# cpsw_9xuss_j7am0_CPSW_NUSS_VBUSP register map
Vendor: Texas Instruments
Peripheral module from a debugger description file (folder J7_AHP).
Registers are 32-bit, read-write, reset 0x0 unless marked. A register's access mark holds for its fields unless they carry their own. Offsets are as the file gives them; lines under a group give offsets from that group; [hi:lo] are bit positions; {n}, {i} and the like mark numbered series; 'fields as' and 'values as' point back to an identical list; <NAME> marks a mode.

## cpsw_9xuss_j7am0_CPSW_NUSS_VBUSP (part 1 of 3)
0x34 CPSW_NUSS_VBUSP_P0_LPI2WAKE_REG
  [23:0] COUNT — Port 0 EEE LPI to wake counter load value
0x34 CPSW_NUSS_VBUSP_PN_LPI2WAKE_REG
  [23:0] COUNT — EEE LPI to wake counter load value
0x34 CPSW_NUSS_VBUSP_PN_LPI2WAKE_REG
  [23:0] COUNT — EEE LPI to wake counter load value
0x34 CPSW_NUSS_VBUSP_PN_LPI2WAKE_REG
  [23:0] COUNT — EEE LPI to wake counter load value
0x34 CPSW_NUSS_VBUSP_PN_LPI2WAKE_REG
  [23:0] COUNT — EEE LPI to wake counter load value
0x34 CPSW_NUSS_VBUSP_PN_LPI2WAKE_REG
  [23:0] COUNT — EEE LPI to wake counter load value
0x34 CPSW_NUSS_VBUSP_PN_LPI2WAKE_REG
  [23:0] COUNT — EEE LPI to wake counter load value
0x34 CPSW_NUSS_VBUSP_PN_LPI2WAKE_REG
  [23:0] COUNT — EEE LPI to wake counter load value
0x34 CPSW_NUSS_VBUSP_PN_LPI2WAKE_REG
  [23:0] COUNT — EEE LPI to wake counter load value
0x34 CPSW_NUSS_VBUSP_TXGOODFRAMES
  [31:0] COUNT — Total number of good frames transmitted
0x34 CPSW_NUSS_VBUSP_EVENT_0_REG ro
  [31:0] TIME_STAMP
0x34 CPSW_NUSS_VBUSP_ALE_TBLW2
  [10:0] TABLEWRD2 — Table Entry bits [75:64]
0x38 CPSW_NUSS_VBUSP_AUX_CFG_REG
  [31:0] AUX_CFG — Auxiliary configuration register output
0x38 CPSW_NUSS_VBUSP_POLL_EN_REG reset 0xFFFFFFFF
  [31:0] POLL_EN — MDIO Poll Enable
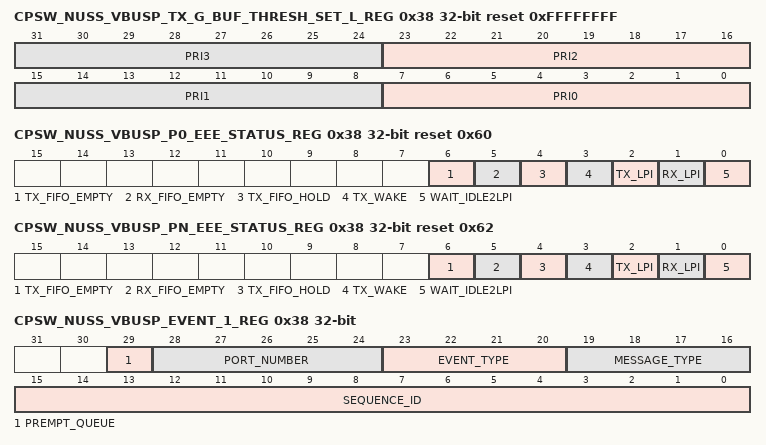
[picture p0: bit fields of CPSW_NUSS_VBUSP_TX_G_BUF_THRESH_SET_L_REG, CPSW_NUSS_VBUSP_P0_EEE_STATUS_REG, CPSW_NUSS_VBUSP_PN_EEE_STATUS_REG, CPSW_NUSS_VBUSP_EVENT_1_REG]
0x38 CPSW_NUSS_VBUSP_TX_G_BUF_THRESH_SET_L_REG reset 0xFFFFFFFF
  [8n+7:8n] PRI{n} (n=0..3) — Priority Based Flow Control Global Buffer Usage Threshold for Priority {n}
0x38 CPSW_NUSS_VBUSP_P0_EEE_STATUS_REG ro reset 0x60
  [6] TX_FIFO_EMPTY — CPPI port 0 transmit FIFO (switch egress) is empty - contains no packets
  [5] RX_FIFO_EMPTY — CPPI port 0 receive FIFO (switch ingress) is empty - contains no packets
  [4] TX_FIFO_HOLD — CPPI port 0 transmit FIFO hold - asserted in the LPI state and during the LPI2WAKE count time
  [3] TX_WAKE — CPPI port 0 transmit wakeup - asserted in the transmit LPI2WAKE count time
  [2] TX_LPI — CPPI port 0 transmit LPI state - asserted when the port 0 transmit is in the LPI state
  [1] RX_LPI — CPPI port 0 receive LPI state - asserted when the port 0 receive is in the LPI state
  [0] WAIT_IDLE2LPI — CPPI port 0 wait idle to LPI - asserted when port 0 is counting the IDLE2LPI time
0x38 CPSW_NUSS_VBUSP_PN_EEE_STATUS_REG ro reset 0x62
  [6] TX_FIFO_EMPTY — Transmit FIFO (switch egress) is empty - contains no packets
  [5] RX_FIFO_EMPTY — Receive FIFO (switch ingress) is empty - contains no packets
  [4] TX_FIFO_HOLD — Transmit FIFO hold - asserted in the LPI state and during the LPI2WAKE count time
  [3] TX_WAKE — Transmit wakeup - asserted in the transmit LPI2WAKE count time
  [2] TX_LPI — Transmit LPI state - asserted when the port 0 transmit is in the LPI state
  [1] RX_LPI — Receive LPI state - asserted when the port 0 receive is in the LPI state
  [0] WAIT_IDLE2LPI — CPPI port 0 wait idle to LPI - asserted when port 0 is counting the IDLE2LPI time
0x38 CPSW_NUSS_VBUSP_PN_EEE_STATUS_REG ro reset 0x62
  fields as CPSW_NUSS_VBUSP_PN_EEE_STATUS_REG
0x38 CPSW_NUSS_VBUSP_PN_EEE_STATUS_REG ro reset 0x62
  fields as CPSW_NUSS_VBUSP_PN_EEE_STATUS_REG
0x38 CPSW_NUSS_VBUSP_PN_EEE_STATUS_REG ro reset 0x62
  fields as CPSW_NUSS_VBUSP_PN_EEE_STATUS_REG
0x38 CPSW_NUSS_VBUSP_PN_EEE_STATUS_REG ro reset 0x62
  fields as CPSW_NUSS_VBUSP_PN_EEE_STATUS_REG
0x38 CPSW_NUSS_VBUSP_PN_EEE_STATUS_REG ro reset 0x62
  fields as CPSW_NUSS_VBUSP_PN_EEE_STATUS_REG
0x38 CPSW_NUSS_VBUSP_PN_EEE_STATUS_REG ro reset 0x62
  fields as CPSW_NUSS_VBUSP_PN_EEE_STATUS_REG
0x38 CPSW_NUSS_VBUSP_PN_EEE_STATUS_REG ro reset 0x62
  fields as CPSW_NUSS_VBUSP_PN_EEE_STATUS_REG
0x38 CPSW_NUSS_VBUSP_TXBROADCASTFRAMES
  [31:0] COUNT — Total number of good broadcast frames transmitted
0x38 CPSW_NUSS_VBUSP_EVENT_1_REG ro
  [29] PREMPT_QUEUE, [28:24] PORT_NUMBER, [23:20] EVENT_TYPE, [19:16] MESSAGE_TYPE, [15:0] SEQUENCE_ID
0x38 CPSW_NUSS_VBUSP_ALE_TBLW1
  [31:0] TABLEWRD1 — Table Entry bits [63:32]
0x3C CPSW_NUSS_VBUSP_CLAUS45_REG
  [31:0] CLAUSE45 — MDIO Clause 45
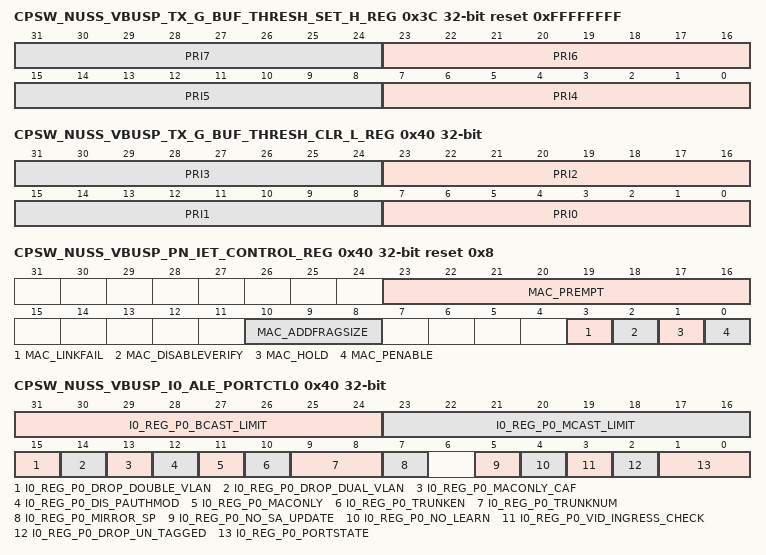
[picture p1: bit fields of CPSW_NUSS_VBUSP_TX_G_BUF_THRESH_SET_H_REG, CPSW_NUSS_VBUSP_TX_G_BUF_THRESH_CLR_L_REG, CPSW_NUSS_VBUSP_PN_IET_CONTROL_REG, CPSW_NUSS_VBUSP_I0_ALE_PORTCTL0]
0x3C CPSW_NUSS_VBUSP_TX_G_BUF_THRESH_SET_H_REG reset 0xFFFFFFFF
  [8n-25:8n-32] PRI{n} (n=4..7) — Priority Based Flow Control Global Buffer Usage Threshold for Priority {n}
0x3C CPSW_NUSS_VBUSP_TXMULTICASTFRAMES
  [31:0] COUNT — Total number of good multicast frames transmitted
0x3C CPSW_NUSS_VBUSP_EVENT_2_REG ro
  [7:0] DOMAIN
0x3C CPSW_NUSS_VBUSP_ALE_TBLW0
  [31:0] TABLEWRD0 — Table Entry bits [31:0]
0x40 CPSW_NUSS_VBUSP_DIAG_CLEAR_REG
  [0] DIAG_CLEAR — Diagnostics clear
0x40 CPSW_NUSS_VBUSP_USER_ADDR0_REG
  [15:0] USER_ADDR0 — MDIO USER Address 0
0x40 CPSW_NUSS_VBUSP_TX_G_BUF_THRESH_CLR_L_REG
  fields as CPSW_NUSS_VBUSP_TX_G_BUF_THRESH_SET_L_REG
0x40 CPSW_NUSS_VBUSP_PN_IET_CONTROL_REG reset 0x8
  [23:16] MAC_PREMPT — IET MAC Fragment Size
  [10:8] MAC_ADDFRAGSIZE — IET MAC Fragment Size
  [3] MAC_LINKFAIL — IET MAC LINK Fail Reset
  [2] MAC_DISABLEVERIFY — IET MAC Disable Verify
  [1] MAC_HOLD — IET MAC HOLD
  [0] MAC_PENABLE — IET MAC Penable
0x40 CPSW_NUSS_VBUSP_PN_IET_CONTROL_REG reset 0x8
  fields as CPSW_NUSS_VBUSP_PN_IET_CONTROL_REG
0x40 CPSW_NUSS_VBUSP_PN_IET_CONTROL_REG reset 0x8
  fields as CPSW_NUSS_VBUSP_PN_IET_CONTROL_REG
0x40 CPSW_NUSS_VBUSP_PN_IET_CONTROL_REG reset 0x8
  fields as CPSW_NUSS_VBUSP_PN_IET_CONTROL_REG
0x40 CPSW_NUSS_VBUSP_PN_IET_CONTROL_REG reset 0x8
  fields as CPSW_NUSS_VBUSP_PN_IET_CONTROL_REG
0x40 CPSW_NUSS_VBUSP_PN_IET_CONTROL_REG reset 0x8
  fields as CPSW_NUSS_VBUSP_PN_IET_CONTROL_REG
0x40 CPSW_NUSS_VBUSP_PN_IET_CONTROL_REG reset 0x8
  fields as CPSW_NUSS_VBUSP_PN_IET_CONTROL_REG
0x40 CPSW_NUSS_VBUSP_PN_IET_CONTROL_REG reset 0x8
  fields as CPSW_NUSS_VBUSP_PN_IET_CONTROL_REG
0x40 CPSW_NUSS_VBUSP_TXPAUSEFRAMES
  [31:0] COUNT — Total number of pause frames transmitted
0x40 CPSW_NUSS_VBUSP_EVENT_3_REG ro
  [31:0] TIME_STAMP
0x40 CPSW_NUSS_VBUSP_I0_ALE_PORTCTL0
  [31:24] I0_REG_P0_BCAST_LIMIT — Broadcast Packet Rate Limit - Each prescale pulse loads this field into the port broadcast rate limit counter. The port counters are decremented with each packet received or transmitted depending on whether the mode is transmit or receive. If the counters decrement to zero, then further packets are rate limited until the next prescale pulse. Broadcast rate limiting is enabled by a non-zero value in this field.
  [23:16] I0_REG_P0_MCAST_LIMIT — Multicast Packet Rate Limit - Each prescale pulse loads this field into the port multicast rate limit counter. The port counters are decremented with each packet received or transmitted depending on whether the mode is transmit or receive. If the counters decrement to zero, then further packets are rate limited until the next prescale pulse. Multicast rate limiting is enabled by a non-zero value in this field.The ~imcast_limit is the number of Multicast packets that will be forwaded per ~iale_prescale time.
  [15] I0_REG_P0_DROP_DOUBLE_VLAN — Drop Double VLAN - When set cause any received packet with double VLANs to be dropped. That is if there are two ctag or two stag fields in the packet it will be dropped.
  [14] I0_REG_P0_DROP_DUAL_VLAN — Drop Dual VLAN - When set will cause any received packet with dual VLAN stag followed by ctag to be dropped.
  [13] I0_REG_P0_MACONLY_CAF — Mac Only Copy All Frames - When set a Mac Only port will transfer all received good frames to the host. When clear a Mac Only port will transfer packets to the host based on ALE destination address lookup operation (which operates more like an Ethernet Mac). A Mac Only port is a port with ~imaconly set.
  [12] I0_REG_P0_DIS_PAUTHMOD — Disable Port authorization - When set will allow unknown addresses to arrive on a switch in authorization mode. It is intended for device to device network connection on ports which do not require MACSEC encryption.
  [11] I0_REG_P0_MACONLY — MAC Only - When set enables this port be treated like a MAC port for the host. All traffic received is only sent to the host. The host must direct traffic to this port as the lookup engine will not send traffic to the ports with the ~ip0_maconly bit set and the ~ip0_no_learn also set. If ~ip0_maconly bit is set and the ~ip0_no_learn is not set, the host can send non-directed packets that can be sent to the destination of a MacOnly port. It is also possible that The host can broadcast to all ports including MacOnly ports in this mode.
  [10] I0_REG_P0_TRUNKEN — Trunk Enable - This field is used to enable a port into a trunk. Any port can be used as a trunk port, any two or more ports with the ~ip0_trunken its set and having the same ~ip0_trunknum will be placed in the same trunk. There is no requirement for trunk ports to be adjacent. If all ports are enabled in the same trunk, no traffic can flow as traffic received within a trunk is never trasnmitted out the same trunk. If only a single port is a member of a trunk, it looks like a normal port with exception of entries in the look up table will be noted as a trunk entry.
  [9:8] I0_REG_P0_TRUNKNUM — Trunk Number - This field is used as the trunk number when the ~ip0_trunken is also set. Ports with the same trunk number that have the ~ip0_trunken also set will have traffic distributed within the trunk based on the result of the hash function descrived above.
  [7] I0_REG_P0_MIRROR_SP — Mirror Source Port - This field enables the source port mirror option. When this bit is set any traffic received on the port with the reg_p0_mirror_sp bit set will have its received traffic also sent to the ~imirror_top port.
  [5] I0_REG_P0_NO_SA_UPDATE — No Source Address Update - When set will not update the source addresses for this port.
  [4] I0_REG_P0_NO_LEARN — No Learn - When set will not learn the source addresses for this port.
  [3] I0_REG_P0_VID_INGRESS_CHECK — VLAN Ingress Check - When set if a packet received is not a member of the VLAN, the packet will be dropped.
  [2] I0_REG_P0_DROP_UN_TAGGED — If Drop Untagged - When set will drop packets without a VLAN tag.
  [1:0] I0_REG_P0_PORTSTATE — Port State - Defins the current port state used for lookup operations. 0 - Disabled 1 - Blocked 2 - Learning 3 - Forwarding
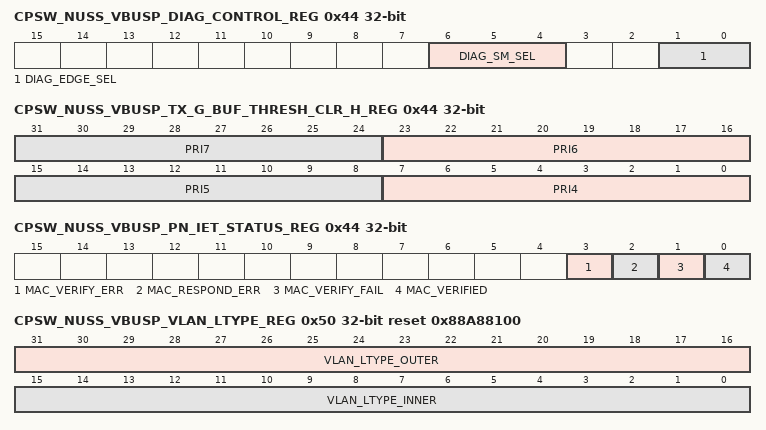
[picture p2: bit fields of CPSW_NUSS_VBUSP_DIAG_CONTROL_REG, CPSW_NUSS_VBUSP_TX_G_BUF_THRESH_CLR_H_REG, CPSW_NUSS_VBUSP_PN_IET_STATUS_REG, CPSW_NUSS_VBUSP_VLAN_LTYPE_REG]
0x44 CPSW_NUSS_VBUSP_DIAG_CONTROL_REG
  [6:4] DIAG_SM_SEL — Diagnostic select
  [1:0] DIAG_EDGE_SEL — Diagnostics hold signals edge select
0x44 CPSW_NUSS_VBUSP_USER_ADDR1_REG
  [15:0] USER_ADDR1 — MDIO USER Address 1
0x44 CPSW_NUSS_VBUSP_TX_G_BUF_THRESH_CLR_H_REG
  fields as CPSW_NUSS_VBUSP_TX_G_BUF_THRESH_SET_H_REG
0x44 CPSW_NUSS_VBUSP_PN_IET_STATUS_REG ro
  [3] MAC_VERIFY_ERR — IET MAC VERIFY ERROR
  [2] MAC_RESPOND_ERR — IET MAC RESPONSE ERROR
  [1] MAC_VERIFY_FAIL — IET MAC VERIFY FAIL
  [0] MAC_VERIFIED — IET MAC VERIFIED
0x44 CPSW_NUSS_VBUSP_PN_IET_STATUS_REG ro
  fields as CPSW_NUSS_VBUSP_PN_IET_STATUS_REG
0x44 CPSW_NUSS_VBUSP_PN_IET_STATUS_REG ro
  fields as CPSW_NUSS_VBUSP_PN_IET_STATUS_REG
0x44 CPSW_NUSS_VBUSP_PN_IET_STATUS_REG ro
  fields as CPSW_NUSS_VBUSP_PN_IET_STATUS_REG
0x44 CPSW_NUSS_VBUSP_PN_IET_STATUS_REG ro
  fields as CPSW_NUSS_VBUSP_PN_IET_STATUS_REG
0x44 CPSW_NUSS_VBUSP_PN_IET_STATUS_REG ro
  fields as CPSW_NUSS_VBUSP_PN_IET_STATUS_REG
0x44 CPSW_NUSS_VBUSP_PN_IET_STATUS_REG ro
  fields as CPSW_NUSS_VBUSP_PN_IET_STATUS_REG
0x44 CPSW_NUSS_VBUSP_PN_IET_STATUS_REG ro
  fields as CPSW_NUSS_VBUSP_PN_IET_STATUS_REG
0x44 CPSW_NUSS_VBUSP_TXDEFERREDFRAMES
  [31:0] COUNT — Total number of deferred frames transmitted
0x44 CPSW_NUSS_VBUSP_TS_LOAD_HIGH_VAL_REG
  [31:0] TS_LOAD_VAL — Time stamp load high value
0x48 CPSW_NUSS_VBUSP_DIAG_STATUS_REG ro
  [15:0] DIAG_STATUS — Diagnostics status
0x48 CPSW_NUSS_VBUSP_PN_IET_VERIFY_REG reset 0x1312D0
  [23:0] MAC_VERIFY_CNT — IET MAC VERIFY COUNT
0x48 CPSW_NUSS_VBUSP_PN_IET_VERIFY_REG reset 0x1312D0
  [23:0] MAC_VERIFY_CNT — IET MAC VERIFY COUNT
0x48 CPSW_NUSS_VBUSP_PN_IET_VERIFY_REG reset 0x1312D0
  [23:0] MAC_VERIFY_CNT — IET MAC VERIFY COUNT
0x48 CPSW_NUSS_VBUSP_PN_IET_VERIFY_REG reset 0x1312D0
  [23:0] MAC_VERIFY_CNT — IET MAC VERIFY COUNT
0x48 CPSW_NUSS_VBUSP_PN_IET_VERIFY_REG reset 0x1312D0
  [23:0] MAC_VERIFY_CNT — IET MAC VERIFY COUNT
0x48 CPSW_NUSS_VBUSP_PN_IET_VERIFY_REG reset 0x1312D0
  [23:0] MAC_VERIFY_CNT — IET MAC VERIFY COUNT
0x48 CPSW_NUSS_VBUSP_PN_IET_VERIFY_REG reset 0x1312D0
  [23:0] MAC_VERIFY_CNT — IET MAC VERIFY COUNT
0x48 CPSW_NUSS_VBUSP_PN_IET_VERIFY_REG reset 0x1312D0
  [23:0] MAC_VERIFY_CNT — IET MAC VERIFY COUNT
0x48 CPSW_NUSS_VBUSP_TXCOLLISIONFRAMES
  [31:0] COUNT — Total number of transmitted frames experiencing a collision
0x48 CPSW_NUSS_VBUSP_TS_COMP_HIGH_VAL_REG
  [31:0] TS_COMP_HIGH_VAL — Time stamp comparison high value
0x4C CPSW_NUSS_VBUSP_TXSINGLECOLLFRAMES
  [31:0] COUNT — Total number of transmitted frames experiencing a single collision
0x4C CPSW_NUSS_VBUSP_TS_ADD_VAL_REG
  [2:0] ADD_VAL — Add Value
0x50 CPSW_NUSS_VBUSP_VLAN_LTYPE_REG reset 0x88A88100
  [31:16] VLAN_LTYPE_OUTER — Outer VLAN LType
  [15:0] VLAN_LTYPE_INNER — Inner VLAN LType
0x50 CPSW_NUSS_VBUSP_P0_FIFO_STATUS_REG ro
  [7:0] TX_PRI_ACTIVE — Port 0 FIFO Status
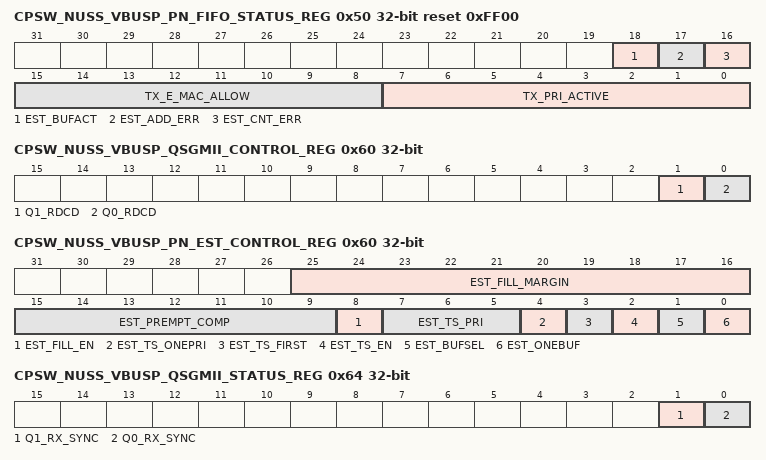
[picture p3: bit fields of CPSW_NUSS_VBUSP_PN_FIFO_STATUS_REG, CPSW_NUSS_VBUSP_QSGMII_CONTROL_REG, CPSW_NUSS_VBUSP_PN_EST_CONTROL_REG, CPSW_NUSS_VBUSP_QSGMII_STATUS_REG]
0x50 CPSW_NUSS_VBUSP_PN_FIFO_STATUS_REG ro reset 0xFF00
  [18] EST_BUFACT — Transmit FIFO EST Buffer Active
  [17] EST_ADD_ERR — Transmit FIFO EST Address Error
  [16] EST_CNT_ERR — Transmit FIFO EST Count Error
  [15:8] TX_E_MAC_ALLOW — Transmit FIFO Express Queue Priority Allow
  [7:0] TX_PRI_ACTIVE — Transmit FIFO Priority Active
0x50 CPSW_NUSS_VBUSP_PN_FIFO_STATUS_REG ro reset 0xFF00
  fields as CPSW_NUSS_VBUSP_PN_FIFO_STATUS_REG
0x50 CPSW_NUSS_VBUSP_PN_FIFO_STATUS_REG ro reset 0xFF00
  fields as CPSW_NUSS_VBUSP_PN_FIFO_STATUS_REG
0x50 CPSW_NUSS_VBUSP_PN_FIFO_STATUS_REG ro reset 0xFF00
  fields as CPSW_NUSS_VBUSP_PN_FIFO_STATUS_REG
0x50 CPSW_NUSS_VBUSP_PN_FIFO_STATUS_REG ro reset 0xFF00
  fields as CPSW_NUSS_VBUSP_PN_FIFO_STATUS_REG
0x50 CPSW_NUSS_VBUSP_PN_FIFO_STATUS_REG ro reset 0xFF00
  fields as CPSW_NUSS_VBUSP_PN_FIFO_STATUS_REG
0x50 CPSW_NUSS_VBUSP_PN_FIFO_STATUS_REG ro reset 0xFF00
  fields as CPSW_NUSS_VBUSP_PN_FIFO_STATUS_REG
0x50 CPSW_NUSS_VBUSP_PN_FIFO_STATUS_REG ro reset 0xFF00
  fields as CPSW_NUSS_VBUSP_PN_FIFO_STATUS_REG
0x50 CPSW_NUSS_VBUSP_TXMULTCOLLFRAMES
  [31:0] COUNT — Total number of transmitted frames experiencing multiple collisions
0x50 CPSW_NUSS_VBUSP_TS_PPM_LOW_VAL_REG
  [31:0] TS_PPM_LOW_VAL — Time stamp PPM Low value
0x54 CPSW_NUSS_VBUSP_EST_TS_DOMAIN_REG
  [7:0] EST_TS_DOMAIN — Enhanced Scheduled Traffic Host Event Domain
0x54 CPSW_NUSS_VBUSP_TXEXCESSIVECOLLISIONS
  [31:0] COUNT — Total number of transmitted frames abandoned due to excessive collisions
0x54 CPSW_NUSS_VBUSP_TS_PPM_HIGH_VAL_REG
  [9:0] TS_PPM_HIGH_VAL — Time stamp PPM High value
0x58 CPSW_NUSS_VBUSP_TXLATECOLLISIONS
  [31:0] COUNT — Total number of transmitted frames abandoned due to a late collision
0x58 CPSW_NUSS_VBUSP_TS_NUDGE_VAL_REG
  [7:0] TS_NUDGE_VAL — Time stamp Nudge value
0x5C CPSW_NUSS_VBUSP_RXIPGERROR
  [31:0] COUNT — Total number of receive inter-packet gap errors (10G only)
0x60 CPSW_NUSS_VBUSP_QSGMII_CONTROL_REG
  [1] Q1_RDCD — QSGMII1 Running Disparity Check Disable
  [0] Q0_RDCD — QSGMII0 Running Disparity Check Disable
0x60 CPSW_NUSS_VBUSP_PN_EST_CONTROL_REG
  [25:16] EST_FILL_MARGIN — Transmit FIFO EST Fill Margin
  [15:9] EST_PREMPT_COMP — Transmit FIFO EST Prempt Comparison Value to Clear wire
  [8] EST_FILL_EN — Transmit FIFO EST Fill Enable
  [7:5] EST_TS_PRI — Transmit FIFO EST TimeStamp Priority
  [4] EST_TS_ONEPRI — Transmit FIFO EST TimeStamp One Priority
  [3] EST_TS_FIRST — Transmit FIFO EST TimeStamp First Express Packet
  [2] EST_TS_EN — Transmit FIFO EST TimeStamp Enable
  [1] EST_BUFSEL — Transmit FIFO EST Buffer Select
  [0] EST_ONEBUF — Transmit FIFO EST One Buffer
0x60 CPSW_NUSS_VBUSP_PN_EST_CONTROL_REG
  fields as CPSW_NUSS_VBUSP_PN_EST_CONTROL_REG
0x60 CPSW_NUSS_VBUSP_PN_EST_CONTROL_REG
  fields as CPSW_NUSS_VBUSP_PN_EST_CONTROL_REG
0x60 CPSW_NUSS_VBUSP_PN_EST_CONTROL_REG
  fields as CPSW_NUSS_VBUSP_PN_EST_CONTROL_REG
0x60 CPSW_NUSS_VBUSP_PN_EST_CONTROL_REG
  fields as CPSW_NUSS_VBUSP_PN_EST_CONTROL_REG
0x60 CPSW_NUSS_VBUSP_PN_EST_CONTROL_REG
  fields as CPSW_NUSS_VBUSP_PN_EST_CONTROL_REG
0x60 CPSW_NUSS_VBUSP_PN_EST_CONTROL_REG
  fields as CPSW_NUSS_VBUSP_PN_EST_CONTROL_REG
0x60 CPSW_NUSS_VBUSP_PN_EST_CONTROL_REG
  fields as CPSW_NUSS_VBUSP_PN_EST_CONTROL_REG
0x60 CPSW_NUSS_VBUSP_TXCARRIERSENSEERRORS
  [31:0] COUNT — Total number of transmitted frames that experienced a carrier loss
0x64 CPSW_NUSS_VBUSP_QSGMII_STATUS_REG ro
  [1] Q1_RX_SYNC — QSGMII1 RX Sync Detected
  [0] Q0_RX_SYNC — QSGMII0 RX Sync Detected
0x64 CPSW_NUSS_VBUSP_TXOCTETS
  [31:0] COUNT — Total number of bytes in all good frames transmitted
0x68 CPSW_NUSS_VBUSP_OCTETFRAMES64
  [31:0] COUNT — Total number of 64-byte frames received and transmitted
0x6C CPSW_NUSS_VBUSP_OCTETFRAMES65T127
  [31:0] COUNT — Total number of frames of size 65 to 127 bytes received and transmitted
0x70 CPSW_NUSS_VBUSP_OCTETFRAMES128T255
  [31:0] COUNT — Total number of frames of size 128 to 255 bytes received and transmitted
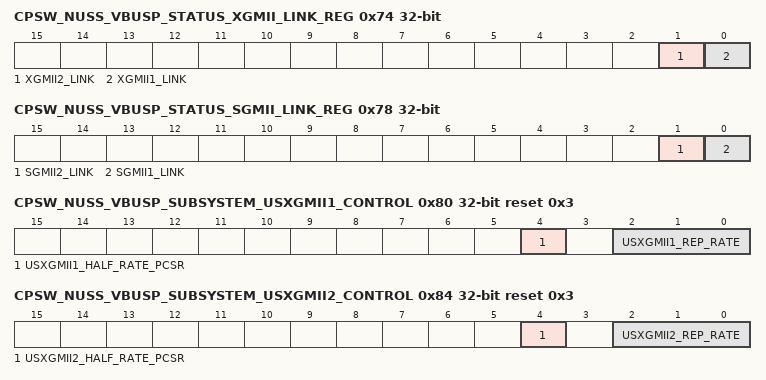
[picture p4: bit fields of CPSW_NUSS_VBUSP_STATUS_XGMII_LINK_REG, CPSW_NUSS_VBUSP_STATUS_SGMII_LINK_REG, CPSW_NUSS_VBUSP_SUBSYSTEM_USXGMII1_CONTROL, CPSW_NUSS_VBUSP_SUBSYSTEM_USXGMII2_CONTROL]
0x74 CPSW_NUSS_VBUSP_STATUS_XGMII_LINK_REG ro
  [1] XGMII2_LINK — Port 2 XGMII Link Indicator
  [0] XGMII1_LINK — Port 1 XGMII Link Indicator
0x74 CPSW_NUSS_VBUSP_OCTETFRAMES256T511
  [31:0] COUNT — Total number of frames of size 256 to 511 bytes received and transmitted
0x78 CPSW_NUSS_VBUSP_STATUS_SGMII_LINK_REG ro
  [1] SGMII2_LINK — Port 2 SGMII Link Indicator
  [0] SGMII1_LINK — Port 1 SGMII Link Indicator
0x78 CPSW_NUSS_VBUSP_OCTETFRAMES512T1023
  [31:0] COUNT — Total number of frames of size 512 to 1023 bytes received and transmitted
0x7C CPSW_NUSS_VBUSP_OCTETFRAMES1024TUP
  [31:0] COUNT — Total number of frames of size 1024 to rx_maxlen bytes received and 1024 bytes or greater transmitted
0x80 CPSW_NUSS_VBUSP_SUBSYSTEM_USXGMII1_CONTROL reset 0x3
  [4] USXGMII1_HALF_RATE_PCSR — USXGMII1 Half Rate
  [2:0] USXGMII1_REP_RATE
0x80 CPSW_NUSS_VBUSP_NETOCTETS
  [31:0] COUNT — Total number of bytes received and transmitted
0x84 CPSW_NUSS_VBUSP_SUBSYSTEM_USXGMII2_CONTROL reset 0x3
  [4] USXGMII2_HALF_RATE_PCSR — USXGMII2 Half Rate
  [2:0] USXGMII2_REP_RATE
0x84 CPSW_NUSS_VBUSP_RX_BOTTOM_OF_FIFO_DROP
  [31:0] COUNT — Receive Bottom of FIFO Drop
0x88 CPSW_NUSS_VBUSP_PORTMASK_DROP
  [31:0] COUNT — Total number of dropped frames received due to portmask
0x8C CPSW_NUSS_VBUSP_RX_TOP_OF_FIFO_DROP
  [31:0] COUNT — Receive Top of FIFO Drop
0x90 CPSW_NUSS_VBUSP_ALE_RATE_LIMIT_DROP
  [31:0] COUNT — Total number of dropped frames due to ALE Rate Limiting
0x90 CPSW_NUSS_VBUSP_ALE_UVLAN_MEMBER
  [8:0] UVLAN_MEMBER_LIST — Unknown VLAN Member List - Each bit represents the port member status for unknown VLANs.
0x94 CPSW_NUSS_VBUSP_ALE_VID_INGRESS_DROP
  [31:0] COUNT — Total number of dropped frames due to ALE VID Ingress
0x94 CPSW_NUSS_VBUSP_ALE_UVLAN_URCAST
  [8:0] UVLAN_UNREG_MCAST_FLOOD_MASK — Unknown VLAN Unregister Multicast Flood Mask - Each bit represents the port to which unregistered multicast are sent for unregistered VLANs.
0x98 CPSW_NUSS_VBUSP_ALE_DA_EQ_SA_DROP
  [31:0] COUNT — Total number of dropped frames due to DA=SA
0x98 CPSW_NUSS_VBUSP_ALE_UVLAN_RMCAST
  [8:0] UVLAN_REG_MCAST_FLOOD_MASK — Unknown VLAN Register Multicast Flood Mask - Each bit represents the port to which registered multicast are sent for unregistered VLANs. This field is ANDed with the registered multicast mask to determine the destinations for unregistered VLANs.
0x9C CPSW_NUSS_VBUSP_ALE_BLOCK_DROP
  [31:0] COUNT — Total number of dropped frames due to ALE Block Mode
0x9C CPSW_NUSS_VBUSP_ALE_UVLAN_UNTAG
  [8:0] UVLAN_FORCE_UNTAGGED_EGRESS — Unknown VLAN Force Untagged Egress Mask - Each bit represents the port where the VLAN will be removed for unregistered VLANs.
0xA0 CPSW_NUSS_VBUSP_ALE_SECURE_DROP
  [31:0] COUNT — Total number of dropped frames due to ALE Secure Mode
0xA4 CPSW_NUSS_VBUSP_ALE_AUTH_DROP
  [31:0] COUNT — Total number of dropped frames due to ALE Authentication
0xA8 CPSW_NUSS_VBUSP_ALE_UNKN_UNI
  [31:0] COUNT — ALE Receive Unknown Unicast
0xAC CPSW_NUSS_VBUSP_ALE_UNKN_UNI_BCNT
  [31:0] COUNT — ALE Receive Unknown Unicast Bytecount
0xB0 CPSW_NUSS_VBUSP_ALE_UNKN_MLT
  [31:0] COUNT — ALE Receive Unknown Multicast
0xB4 CPSW_NUSS_VBUSP_ALE_UNKN_MLT_BCNT
  [31:0] COUNT — ALE Receive Unknown Multicast Bytecount
0xB4 CPSW_NUSS_VBUSP_ALE_FAST_LUT
  [8:0] FAST_LUT — The ~Fast_LUT field alows any port to be Fast_LUT mode, which will cause all lookup operations to start based on DA/SA and VLAN only. That is any data beyong the first 32 are not used in the lookup process.
0xB8 CPSW_NUSS_VBUSP_ALE_UNKN_BRD
  [31:0] COUNT — ALE Receive Unknown Broadcast
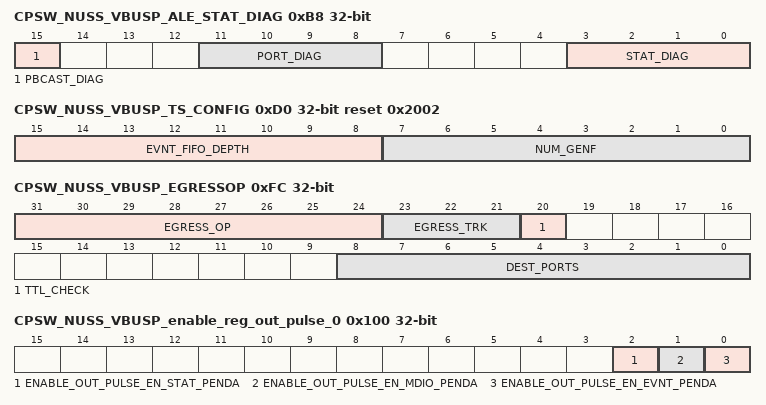
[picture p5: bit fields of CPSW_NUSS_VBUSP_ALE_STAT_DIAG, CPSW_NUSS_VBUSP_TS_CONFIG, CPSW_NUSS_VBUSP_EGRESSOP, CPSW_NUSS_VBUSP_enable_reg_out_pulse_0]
0xB8 CPSW_NUSS_VBUSP_ALE_STAT_DIAG
  [15] PBCAST_DIAG — When set and the ~iport_diag is set to zero, will allow all ports to see the same stat diagnostic increment.
  [11:8] PORT_DIAG — The port selected that a received packet will cause the selected error to increment
  [3:0] STAT_DIAG — When non-zero will cause the selected statistic to increment on the next frame received. For the selected Port. 0: Disabled 1: Destination Equal Source Drop Stat will count 2: VLAN Ingress Check Drop Stat will count 3: Source Multicast Drop Stat will count 4: Dual VLAN Drop Stat will count 5: Ether Type length error Drop Stat will count 6: Next Hop Limit Drop Stat will count 7: IPv4 Fragment Drop Stat will count 8: Classifier Hit Stat will count 9: Classifier Red Drop Stat will count 10: Classifier Yellow Drop Stat will count 11: ALE Overflow Drop Stat will count 12: Rate Limit Drop Stat will count 13: Blocked Address Drop Stat will count 14: Secure Address Drop Stat will count 15: Authorization Drop Stat will count.
0xBC CPSW_NUSS_VBUSP_ALE_UNKN_BRD_BCNT
  [31:0] COUNT — ALE Receive Unknown Broadcast Bytecount
0xBC CPSW_NUSS_VBUSP_ALE_OAM_LB_CTRL
  [8:0] OAM_LB_CTRL — The ~ioam_lb_ctrl allows any port to be put into OAM loopback, that is any packet received will be returned to the same port with an egressop of 0xFF which swaps the source and destination address. BPDUs will still flow through as normal so that OAM can be remotly requested and disabled.
0xC0 CPSW_NUSS_VBUSP_ALE_POL_MATCH
  [31:0] COUNT — ALE Policer Matched
0xC4 CPSW_NUSS_VBUSP_ALE_POL_MATCH_RED
  [31:0] COUNT — ALE Policer Matched and Condition Red
0xC8 CPSW_NUSS_VBUSP_ALE_POL_MATCH_YELLOW
  [31:0] COUNT — ALE Policer Matched and Condition Yellow
0xCC CPSW_NUSS_VBUSP_ALE_MULT_SA_DROP
  [31:0] COUNT — ALE Multicast Source Address drop
0xD0 CPSW_NUSS_VBUSP_ALE_DUAL_VLAN_DROP
  [31:0] COUNT — ALE Dual VLAN drop
0xD0 CPSW_NUSS_VBUSP_TS_CONFIG ro reset 0x2002
  [15:8] EVNT_FIFO_DEPTH — The Event FIFO Depth
  [7:0] NUM_GENF — The number of CPTS GENF outputs
0xD4 CPSW_NUSS_VBUSP_ALE_LEN_ERROR_DROP
  [31:0] COUNT — ALE Length Error drop
0xD8 CPSW_NUSS_VBUSP_ALE_IP_NEXT_HDR_DROP
  [31:0] COUNT — ALE Next Header drop
0xDC CPSW_NUSS_VBUSP_ALE_IPV4_FRAG_DROP
  [31:0] COUNT — ALE IPV4 Fragment drop
0xFC CPSW_NUSS_VBUSP_EGRESSOP
  [31:24] EGRESS_OP — The Egress Operation defines the operation performed by the CPSW Egress Packet Operations 0: NOP : 1-n: Defines which egress Operation will be performed. This allows Inter VLAN routing to be configured for high bandwidth traffic, reducing CPU load. 0xff: Swap SA and DA of packet, this is intended to allow OAM diagnostics for a link.
  [23:21] EGRESS_TRK — The Egress Trunk Index is the calculated trunk index from the SA, DA or VLAN if modified to that InterVLAN routing will work on trunks as well. The DA, SA and VLAN are ignored for trunk generation on InterVLAN Routing so that this field is the index generated from the Egress Op replacements elclusive or'd together into a three bit index.
  [20] TTL_CHECK — The TTL Check will cause any packet that fails TTL checks to not be routed to the Inter VLAN Routing sub functions. The packet will be routed to the host it was destined to.
  [8:0] DEST_PORTS — The Destination Ports is a list of the ports the classified packet will be set to. If a destination is a Trunk, all the port bits for that trunck must be set.
0x100 CPSW_NUSS_VBUSP_enable_reg_out_pulse_0 access not given
  [2] ENABLE_OUT_PULSE_EN_STAT_PENDA — Enable Set for out_pulse_en_stat_penda (access R/W1TS)
  [1] ENABLE_OUT_PULSE_EN_MDIO_PENDA — Enable Set for out_pulse_en_mdio_penda (access R/W1TS)
  [0] ENABLE_OUT_PULSE_EN_EVNT_PENDA — Enable Set for out_pulse_en_evnt_penda (access R/W1TS)
{0x100+4i} CPSW_NUSS_VBUSP_TX_PRI{i}_MAXLEN_REG reset 0x7E8 (i=0..7)
  [13:0] TX_PRI{i}_MAXLEN — Transmit Priority {i} Maximum Length
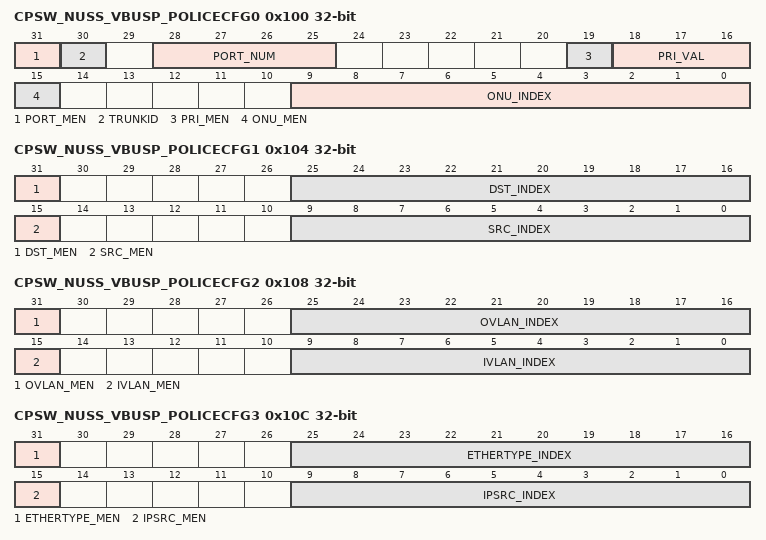
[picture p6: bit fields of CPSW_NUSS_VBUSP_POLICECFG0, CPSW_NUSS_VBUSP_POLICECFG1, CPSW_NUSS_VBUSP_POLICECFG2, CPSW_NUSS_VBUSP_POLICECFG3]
0x100 CPSW_NUSS_VBUSP_POLICECFG0
  [31] PORT_MEN — Port Match Enable - Enabled port match for the selected policing/classifier entry
  [30] TRUNKID — Trunk ID - When set indicates the port number is a trunk group.
  [28:25] PORT_NUM — Port Number - Specifies the port address to match for the selected policing/classifier entry
  [19] PRI_MEN — Priority Match Enable - Enables frame priority match for the selected policing/classifier entry
  [18:16] PRI_VAL — Priority Value - Specifies the frame priority to match for the selected policing/classifier entry
  [15] ONU_MEN — OUI Match Enable - Enables frame ONU address match for the selected policing/classifier entry
  [9:0] ONU_INDEX — OUI Table Entry Index - Specifies the ALE ONU address lookup table index to match for the selected policing/classifier entry
0x104 CPSW_NUSS_VBUSP_POLICECFG1
  [31] DST_MEN — Destination Address Match Enable - Enables frame L2 destination address match for the selected policing/classifier entry
  [25:16] DST_INDEX — Destination Address Table Entry Index - Specifies the ALE L2 destination address lookup table index to match for the selected policing/classifier entry
  [15] SRC_MEN — Source Address Match Enable - Enables frame L2 source address match for the selected policing/classifier entry
  [9:0] SRC_INDEX — Source Address Table Entry Index - Specifies the ALE L2 source address lookup table index to match for the selected policing/classifier entry
0x108 CPSW_NUSS_VBUSP_POLICECFG2
  [31] OVLAN_MEN — Outer VLAN Match Enable - Enables frame Outer VLAN address match for the selected policing/classifier entry
  [25:16] OVLAN_INDEX — Outer VLAN Table Entry Index - Specifies the ALE Outer VLAN address lookup table index to match for the selected policing/classifier entry
  [15] IVLAN_MEN — Inner VLAN Match Enable - Enables frame Inner VLAN address match for the selected policing/classifier entry
  [9:0] IVLAN_INDEX — Inner VLAN Table Entry Index - Specifies the ALE Inner VLAN address lookup table index to match for the selected policing/classifier entry
0x10C CPSW_NUSS_VBUSP_POLICECFG3
  [31] ETHERTYPE_MEN — EtherType Match Enable - Enables frame Ether Type match for the selected policing/classifier entry
  [25:16] ETHERTYPE_INDEX — EtherType Table Entry Index - Specifies the ALE Ether Type lookup table index to match for the selected policing/classifier entry
  [15] IPSRC_MEN — IP Source Address Match Enable - Enables frame IP Source address match for the selected policing/classifier entry
  [9:0] IPSRC_INDEX — IP Source Address Table Entry Index - Specifies the ALE IP Source address lookup table index to match for the selected policing/classifier entry
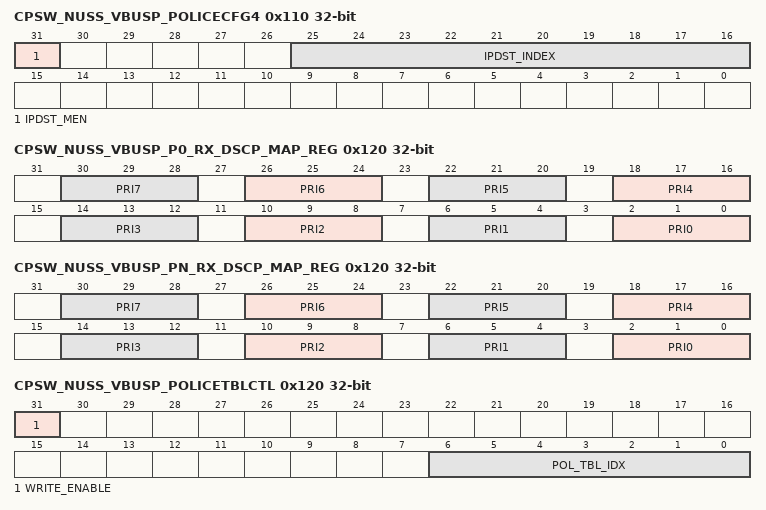
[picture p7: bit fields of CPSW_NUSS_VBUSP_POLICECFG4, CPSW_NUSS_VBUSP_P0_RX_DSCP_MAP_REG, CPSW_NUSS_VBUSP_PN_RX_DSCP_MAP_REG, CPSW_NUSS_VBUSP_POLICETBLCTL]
0x110 CPSW_NUSS_VBUSP_POLICECFG4
  [31] IPDST_MEN — IP Destination Address Match Enable - Enables frame IP Destination address match for the selected policing/classifier entry
  [25:16] IPDST_INDEX — IP Destination Address Table Entry Index - Specifies the ALE IP Destination address lookup table index to match for the selected policing/classifier entry
0x118 CPSW_NUSS_VBUSP_POLICECFG6
  [31:0] PIR_IDLE_INC_VAL — Peak Information Rate Idle Increment Value - The number added to the PIR counter every clock cycle. If zero the PIR counter is disabled and packets will never be marked or processed as RED.
0x11C CPSW_NUSS_VBUSP_POLICECFG7
  [31:0] CIR_IDLE_INC_VAL — Committed Information Idle Increment Value - The number added to the CIR counter every clock cycle. If zero the CIR counter is disabled and packets will never be marked or processed as YELLOW.
0x120 CPSW_NUSS_VBUSP_P0_RX_DSCP_MAP_REG
  [4n+2:4n] PRI{n} (n=0..7) — A DSCP IPV4/V6 packet TOS of N*8+{n} is mapped to this received priority
0x120 CPSW_NUSS_VBUSP_PN_RX_DSCP_MAP_REG
  fields as CPSW_NUSS_VBUSP_P0_RX_DSCP_MAP_REG
0x120 CPSW_NUSS_VBUSP_PN_RX_DSCP_MAP_REG
  fields as CPSW_NUSS_VBUSP_P0_RX_DSCP_MAP_REG
0x120 CPSW_NUSS_VBUSP_PN_RX_DSCP_MAP_REG
  fields as CPSW_NUSS_VBUSP_P0_RX_DSCP_MAP_REG
0x120 CPSW_NUSS_VBUSP_PN_RX_DSCP_MAP_REG
  fields as CPSW_NUSS_VBUSP_P0_RX_DSCP_MAP_REG
0x120 CPSW_NUSS_VBUSP_PN_RX_DSCP_MAP_REG
  fields as CPSW_NUSS_VBUSP_P0_RX_DSCP_MAP_REG
0x120 CPSW_NUSS_VBUSP_PN_RX_DSCP_MAP_REG
  fields as CPSW_NUSS_VBUSP_P0_RX_DSCP_MAP_REG
0x120 CPSW_NUSS_VBUSP_PN_RX_DSCP_MAP_REG
  fields as CPSW_NUSS_VBUSP_P0_RX_DSCP_MAP_REG
0x120 CPSW_NUSS_VBUSP_PN_RX_DSCP_MAP_REG
  fields as CPSW_NUSS_VBUSP_P0_RX_DSCP_MAP_REG
0x120 CPSW_NUSS_VBUSP_POLICETBLCTL
  [31] WRITE_ENABLE — Write Enable - Setting this bit will write the POLICECFG0-7 to the ~ipol_tbl_idx selected policing/classifier entry. Clearing this bit will read the ~ipol_tbl_idx selected policing/classifier entry into the POLICECFG0-7 registers.
  [6:0] POL_TBL_IDX — Policer Entry Index - This field specifies the policing/classifier entry to be read or written. When writing to this field without setting the ~iwrite_enable=1 will cause the selected policing/classifier entry to be loaded into the POLICECFG0-7 registers. When writing to this field with setting the ~iwrite_enable=1 will cause the selected policing/classifier entry to be updated from the POLICECFG0-7 registers.
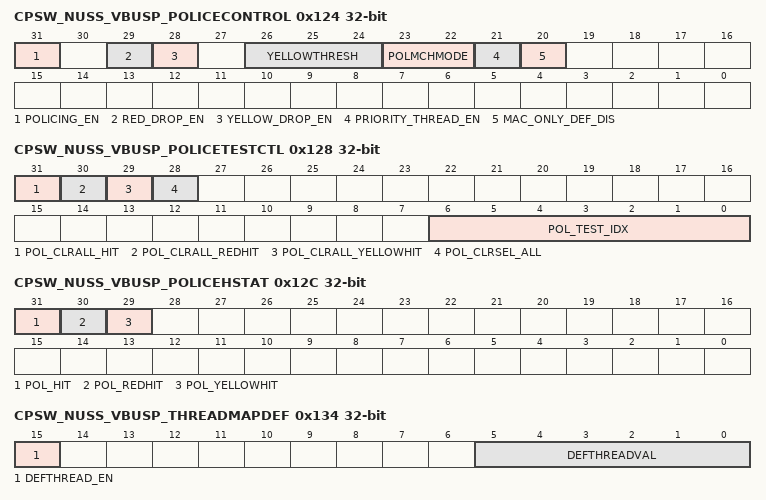
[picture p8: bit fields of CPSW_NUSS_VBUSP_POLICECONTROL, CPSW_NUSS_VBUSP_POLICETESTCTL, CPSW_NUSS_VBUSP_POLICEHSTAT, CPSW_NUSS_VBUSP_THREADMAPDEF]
0x124 CPSW_NUSS_VBUSP_POLICECONTROL
  [31] POLICING_EN — Policing Enable - Enables the policing to color the packets, this also enables red or yellow drop capabilities.
  [29] RED_DROP_EN — RED Drop Enable - Enables the ALE to drop the red colored packets.
  [28] YELLOW_DROP_EN — WELLOW Drop Enable - Enables the ALE to drop yellow packets based on the ~iyellowthresh value. This field would normally not be used as to let the switch drop packets at a buffer threshold instead. In the event that the switch does not enable buffer threshold dropping, YELLOW packets can be dropped based on this feature.
  [26:24] YELLOWTHRESH — Yellow Threshold - When set enables a portion of the yellow packets to be dropped based on the ~iyellow_drop_en enable. 0-100% 1=50% 2-33% 3-25% 4=20% 5-17% 6-14% 7-13%
  [23:22] POLMCHMODE — Policing Match Mode - This field determines what happens to packets that fail to hit any policing/classifier entry. 0 - No Hit packets are marked GREEN 1 - No Hit packets are marked YELLOW 2 - No Hit packets are marked RED 3 - No Hit packets are marked based on policing/classifier entry=0 state.
  [21] PRIORITY_THREAD_EN — Priority Thread Enable - This field determines if priority is OR'd to the default thread when no classifiers hit and the default thread is enabled.
  [20] MAC_ONLY_DEF_DIS — MAC Only Default Disable - This field when set disables the default thread on MAC Only Ports. That is the default thread will be {port,priority}. If the traffic matches a classifier with a thread mapping, the classifier thread mapping still occurs.
0x128 CPSW_NUSS_VBUSP_POLICETESTCTL
  [31] POL_CLRALL_HIT — Policer Clear - This bit clears all the policing/classifier hit bits. This bit is self clearing. This can be used to test the fact that a policing/classifier entry has been hit.
  [30] POL_CLRALL_REDHIT — Policer Clear RED - This bit clears all the policing/classifier RED hit bits. This bit is self clearing. This can be used to test the fact that a policing/classifier entry has been hit during a RED condition.
  [29] POL_CLRALL_YELLOWHIT — Policer Clear YELLOW - This bit clears all the policing/classifier YELLOW hit bits. This bit is self clearing. This can be used to test the fact that a policing/classifier entry has been hit during a YELLOW condition.
  [28] POL_CLRSEL_ALL — Police Clear Selected - This bit clears the selected policing/classifier hit, redhit and yellowhit bits. This bit is self clearing.
  [6:0] POL_TEST_IDX — Policer Test Index - This field selects which policing/classifier hit bits will be read or written.
0x12C CPSW_NUSS_VBUSP_POLICEHSTAT ro
  [31] POL_HIT — Policer Hit - This indicates that the selected policing/classifier via the ~ipol_test_idx field has been hit by a packet seen on any port that matches the policing/classifier entry match.
  [30] POL_REDHIT — Policer Hit RED - This indicates that the selected policing/classifier via the ~ipol_test_idx field has been hit during a RED condition by a packet seen on any port that matches the policing/classifier entry match.
  [29] POL_YELLOWHIT — Policer Hit YELLOW - This indicates that the selected policing/classifier via the ~ipol_test_idx field has been hit during a YELLOW condition by a packet seen on any port that matches the policing/classifier entry match.
0x134 CPSW_NUSS_VBUSP_THREADMAPDEF
  [15] DEFTHREAD_EN — Default Tread Enable - When set the switch will use the ~idefthreadval for the host interface thread ID if no classifier is matched. If clear the switch will generate its own thread ID based on port and priority if there is no classifier match.
  [5:0] DEFTHREADVAL — Default Thread Value - This field specifies the default thread ID value.
0x138 CPSW_NUSS_VBUSP_THREADMAPCTL
  [6:0] CLASSINDEX — Classifier Index - This is the classifier index entry that the thread enable and thread value will be read or written by the ~bTHREADMAPVAL register.
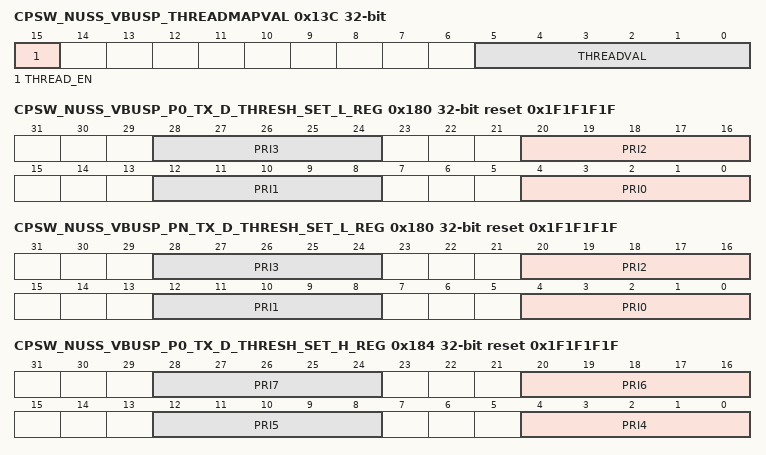
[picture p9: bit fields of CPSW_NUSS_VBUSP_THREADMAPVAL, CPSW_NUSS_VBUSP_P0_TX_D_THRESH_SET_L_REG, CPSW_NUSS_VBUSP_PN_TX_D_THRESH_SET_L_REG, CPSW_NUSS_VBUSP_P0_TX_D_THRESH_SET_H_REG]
0x13C CPSW_NUSS_VBUSP_THREADMAPVAL
  [15] THREAD_EN — Thread Enable - When set the switch will use the ~ithreadval for the selected classifier match. If clear the the thread ID will be determined by the ~bTHREADMAPDEF register settings.
  [5:0] THREADVAL — Thread Value - This field is the thread ID value that is used to map a classifier hit to thread ID for host traffic.
0x140 CPSW_NUSS_VBUSP_P0_PRI_CIR_REG
  [27:0] PRI_CIR — Priority N CIR
0x140 CPSW_NUSS_VBUSP_PN_PRI_CIR_REG
  [27:0] PRI_CIR — Priority N committed information rate
0x140 CPSW_NUSS_VBUSP_PN_PRI_CIR_REG
  [27:0] PRI_CIR — Priority N committed information rate
0x140 CPSW_NUSS_VBUSP_PN_PRI_CIR_REG
  [27:0] PRI_CIR — Priority N committed information rate
0x140 CPSW_NUSS_VBUSP_PN_PRI_CIR_REG
  [27:0] PRI_CIR — Priority N committed information rate
0x140 CPSW_NUSS_VBUSP_PN_PRI_CIR_REG
  [27:0] PRI_CIR — Priority N committed information rate
0x140 CPSW_NUSS_VBUSP_PN_PRI_CIR_REG
  [27:0] PRI_CIR — Priority N committed information rate
0x140 CPSW_NUSS_VBUSP_PN_PRI_CIR_REG
  [27:0] PRI_CIR — Priority N committed information rate
0x140 CPSW_NUSS_VBUSP_PN_PRI_CIR_REG
  [27:0] PRI_CIR — Priority N committed information rate
0x140 CPSW_NUSS_VBUSP_IET_RX_ASSEMBLY_ERROR_REG
  [31:0] IET_RX_ASSEMBLY_ERROR — IET Receive Assembly Error
0x144 CPSW_NUSS_VBUSP_IET_RX_ASSEMBLY_OK_REG
  [31:0] IET_RX_ASSEMBLY_OK — IET Receive Assembly Ok
0x148 CPSW_NUSS_VBUSP_IET_RX_SMD_ERROR_REG
  [31:0] IET_RX_SMD_ERROR — IET Receive Smd Error
0x14C CPSW_NUSS_VBUSP_IET_RX_FRAG_REG
  [31:0] IET_RX_FRAG — IET Receive Frag
0x150 CPSW_NUSS_VBUSP_IET_TX_HOLD_REG
  [31:0] IET_TX_HOLD — IET Transmit Hold
0x154 CPSW_NUSS_VBUSP_IET_TX_FRAG_REG
  [31:0] IET_TX_FRAG — IET Transmit Frag
0x160 CPSW_NUSS_VBUSP_P0_PRI_EIR_REG
  [27:0] PRI_EIR — Priority N EIR
0x160 CPSW_NUSS_VBUSP_PN_PRI_EIR_REG
  [27:0] PRI_EIR — Priority N Excess Information Rate count
0x160 CPSW_NUSS_VBUSP_PN_PRI_EIR_REG
  [27:0] PRI_EIR — Priority N Excess Information Rate count
0x160 CPSW_NUSS_VBUSP_PN_PRI_EIR_REG
  [27:0] PRI_EIR — Priority N Excess Information Rate count
0x160 CPSW_NUSS_VBUSP_PN_PRI_EIR_REG
  [27:0] PRI_EIR — Priority N Excess Information Rate count
0x160 CPSW_NUSS_VBUSP_PN_PRI_EIR_REG
  [27:0] PRI_EIR — Priority N Excess Information Rate count
0x160 CPSW_NUSS_VBUSP_PN_PRI_EIR_REG
  [27:0] PRI_EIR — Priority N Excess Information Rate count
0x160 CPSW_NUSS_VBUSP_PN_PRI_EIR_REG
  [27:0] PRI_EIR — Priority N Excess Information Rate count
0x160 CPSW_NUSS_VBUSP_PN_PRI_EIR_REG
  [27:0] PRI_EIR — Priority N Excess Information Rate count
0x17C CPSW_NUSS_VBUSP_TX_MEMORY_PROTECT_ERROR
  [7:0] COUNT — Transmit Memory Protect CRC Error
0x180 CPSW_NUSS_VBUSP_P0_TX_D_THRESH_SET_L_REG reset 0x1F1F1F1F
  [8n+4:8n] PRI{n} (n=0..3) — Port Priority Based Flow Control Threshold Set Value for Priority {n}
0x180 CPSW_NUSS_VBUSP_PN_TX_D_THRESH_SET_L_REG reset 0x1F1F1F1F
  fields as CPSW_NUSS_VBUSP_P0_TX_D_THRESH_SET_L_REG
0x180 CPSW_NUSS_VBUSP_PN_TX_D_THRESH_SET_L_REG reset 0x1F1F1F1F
  fields as CPSW_NUSS_VBUSP_P0_TX_D_THRESH_SET_L_REG
0x180 CPSW_NUSS_VBUSP_PN_TX_D_THRESH_SET_L_REG reset 0x1F1F1F1F
  fields as CPSW_NUSS_VBUSP_P0_TX_D_THRESH_SET_L_REG
0x180 CPSW_NUSS_VBUSP_PN_TX_D_THRESH_SET_L_REG reset 0x1F1F1F1F
  fields as CPSW_NUSS_VBUSP_P0_TX_D_THRESH_SET_L_REG
0x180 CPSW_NUSS_VBUSP_PN_TX_D_THRESH_SET_L_REG reset 0x1F1F1F1F
  fields as CPSW_NUSS_VBUSP_P0_TX_D_THRESH_SET_L_REG
0x180 CPSW_NUSS_VBUSP_PN_TX_D_THRESH_SET_L_REG reset 0x1F1F1F1F
  fields as CPSW_NUSS_VBUSP_P0_TX_D_THRESH_SET_L_REG
0x180 CPSW_NUSS_VBUSP_PN_TX_D_THRESH_SET_L_REG reset 0x1F1F1F1F
  fields as CPSW_NUSS_VBUSP_P0_TX_D_THRESH_SET_L_REG
0x180 CPSW_NUSS_VBUSP_PN_TX_D_THRESH_SET_L_REG reset 0x1F1F1F1F
  fields as CPSW_NUSS_VBUSP_P0_TX_D_THRESH_SET_L_REG
0x180 CPSW_NUSS_VBUSP_ENET_PN_TX_PRI_REG
  [31:0] PN_TX_PRIN — ENET TX Priority Packet Count
0x184 CPSW_NUSS_VBUSP_P0_TX_D_THRESH_SET_H_REG reset 0x1F1F1F1F
  [8n-28:8n-32] PRI{n} (n=4..7) — Port Priority Based Flow Control Threshold Set Value for Priority {n}
